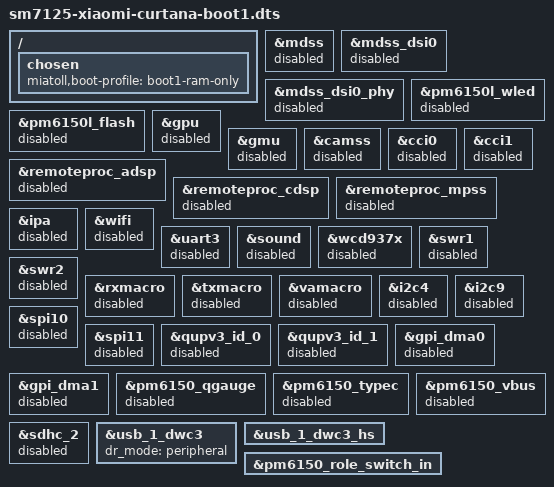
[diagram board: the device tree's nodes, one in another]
// SPDX-License-Identifier: GPL-2.0
// RAM-only first boot: retain inherited simpledrm and USB peripheral console.
#include "sm7125-xiaomi-curtana-huaxing.dts"

/ {
	chosen {
		miatoll,boot-profile = "boot1-ram-only";
	};
};

&mdss { status = "disabled"; };
&mdss_dsi0 { status = "disabled"; };
&mdss_dsi0_phy { status = "disabled"; };
&pm6150l_wled { status = "disabled"; };
&pm6150l_flash { status = "disabled"; };
&gpu { status = "disabled"; };
&gmu { status = "disabled"; };
&camss { status = "disabled"; };
&cci0 { status = "disabled"; };
&cci1 { status = "disabled"; };
&remoteproc_adsp { status = "disabled"; };
&remoteproc_cdsp { status = "disabled"; };
&remoteproc_mpss { status = "disabled"; };
&ipa { status = "disabled"; };
&wifi { status = "disabled"; };
&uart3 { status = "disabled"; };
&sound { status = "disabled"; };
&wcd937x { status = "disabled"; };
&swr1 { status = "disabled"; };
&swr2 { status = "disabled"; };
&rxmacro { status = "disabled"; };
&txmacro { status = "disabled"; };
&vamacro { status = "disabled"; };
&i2c4 { status = "disabled"; };
&i2c9 { status = "disabled"; };
&spi10 { status = "disabled"; };
&spi11 { status = "disabled"; };
&qupv3_id_0 { status = "disabled"; };
&qupv3_id_1 { status = "disabled"; };
&gpi_dma0 { status = "disabled"; };
&gpi_dma1 { status = "disabled"; };
&pm6150_qgauge { status = "disabled"; };
&pm6150_typec { status = "disabled"; };
&pm6150_vbus { status = "disabled"; };
// Leave SD card initialization for a separate test.
&sdhc_2 { status = "disabled"; };

&usb_1_dwc3 {
	dr_mode = "peripheral";
	/delete-property/ usb-role-switch;
};

&usb_1_dwc3_hs {
	/delete-property/ remote-endpoint;
};

&pm6150_role_switch_in {
	/delete-property/ remote-endpoint;
};
